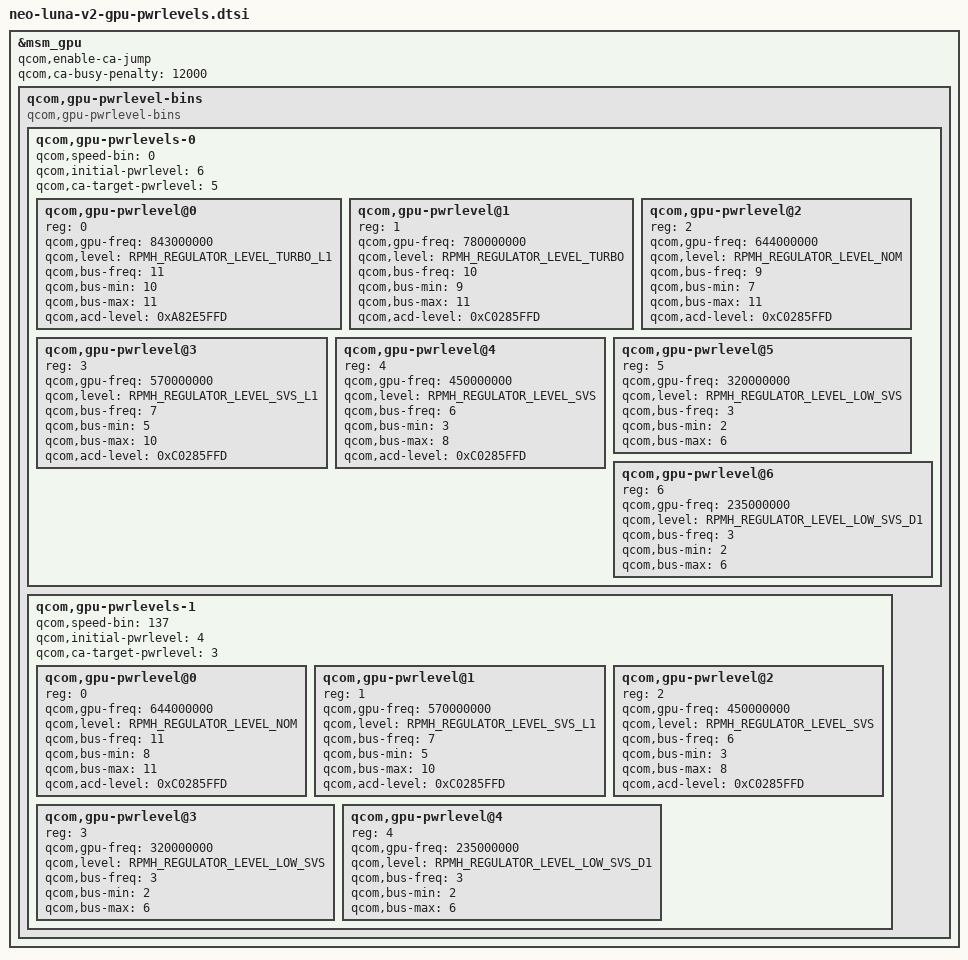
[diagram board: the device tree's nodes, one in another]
&msm_gpu {
	/* Power levels */

	/* Enable context aware freq. scaling */
	qcom,enable-ca-jump;

	/* Context aware jump busy penalty in us */
	qcom,ca-busy-penalty = <12000>;

	/*
	 * Speed-bin zero is default speed bin.
	 * For rest of the speed bins, speed-bin value
	 * is calculated as FMAX/4.8 MHz round up to zero
	 * decimal places plus two margin to account for
	 * clock jitters.
	 */
	qcom,gpu-pwrlevel-bins {
		#address-cells = <1>;
		#size-cells = <0>;

		compatible = "qcom,gpu-pwrlevel-bins";

		qcom,gpu-pwrlevels-0 {
			#address-cells = <1>;
			#size-cells = <0>;

			qcom,speed-bin = <0>;

			qcom,initial-pwrlevel = <6>;
			qcom,ca-target-pwrlevel = <5>;

			/* TURBO_L1 */
			qcom,gpu-pwrlevel@0 {
				reg = <0>;
				qcom,gpu-freq = <843000000>;
				qcom,level = <RPMH_REGULATOR_LEVEL_TURBO_L1>;
				qcom,bus-freq = <11>;
				qcom,bus-min = <10>;
				qcom,bus-max = <11>;

				qcom,acd-level = <0xA82E5FFD>;
			};

			/* TURBO */
			qcom,gpu-pwrlevel@1 {
				reg = <1>;
				qcom,gpu-freq = <780000000>;
				qcom,level = <RPMH_REGULATOR_LEVEL_TURBO>;
				qcom,bus-freq = <10>;
				qcom,bus-min = <9>;
				qcom,bus-max = <11>;

				qcom,acd-level = <0xC0285FFD>;
			};

			/* NOM */
			qcom,gpu-pwrlevel@2 {
				reg = <2>;
				qcom,gpu-freq = <644000000>;
				qcom,level = <RPMH_REGULATOR_LEVEL_NOM>;
				qcom,bus-freq = <9>;
				qcom,bus-min = <7>;
				qcom,bus-max = <11>;

				qcom,acd-level = <0xC0285FFD>;
			};

			/* SVS_L1 */
			qcom,gpu-pwrlevel@3 {
				reg = <3>;
				qcom,gpu-freq = <570000000>;
				qcom,level = <RPMH_REGULATOR_LEVEL_SVS_L1>;
				qcom,bus-freq = <7>;
				qcom,bus-min = <5>;
				qcom,bus-max = <10>;

				qcom,acd-level = <0xC0285FFD>;
			};

			/* SVS */
			qcom,gpu-pwrlevel@4 {
				reg = <4>;
				qcom,gpu-freq = <450000000>;
				qcom,level = <RPMH_REGULATOR_LEVEL_SVS>;
				qcom,bus-freq = <6>;
				qcom,bus-min = <3>;
				qcom,bus-max = <8>;

				qcom,acd-level = <0xC0285FFD>;
			};

			/* LOW SVS */
			qcom,gpu-pwrlevel@5 {
				reg = <5>;
				qcom,gpu-freq = <320000000>;
				qcom,level = <RPMH_REGULATOR_LEVEL_LOW_SVS>;
				qcom,bus-freq = <3>;
				qcom,bus-min = <2>;
				qcom,bus-max = <6>;
			};

			/* LOW SVS_D1 */
			qcom,gpu-pwrlevel@6 {
				reg = <6>;
				qcom,gpu-freq = <235000000>;
				qcom,level = <RPMH_REGULATOR_LEVEL_LOW_SVS_D1>;
				qcom,bus-freq = <3>;
				qcom,bus-min = <2>;
				qcom,bus-max = <6>;
			};
		};

		qcom,gpu-pwrlevels-1 {
			#address-cells = <1>;
			#size-cells = <0>;

			qcom,speed-bin = <137>;

			qcom,initial-pwrlevel = <4>;
			qcom,ca-target-pwrlevel = <3>;

			/* NOM */
			qcom,gpu-pwrlevel@0 {
				reg = <0>;
				qcom,gpu-freq = <644000000>;
				qcom,level = <RPMH_REGULATOR_LEVEL_NOM>;
				qcom,bus-freq = <11>;
				qcom,bus-min = <8>;
				qcom,bus-max = <11>;

				qcom,acd-level = <0xC0285FFD>;
			};

			/* SVS_L1 */
			qcom,gpu-pwrlevel@1 {
				reg = <1>;
				qcom,gpu-freq = <570000000>;
				qcom,level = <RPMH_REGULATOR_LEVEL_SVS_L1>;
				qcom,bus-freq = <7>;
				qcom,bus-min = <5>;
				qcom,bus-max = <10>;

				qcom,acd-level = <0xC0285FFD>;
			};

			/* SVS */
			qcom,gpu-pwrlevel@2 {
				reg = <2>;
				qcom,gpu-freq = <450000000>;
				qcom,level = <RPMH_REGULATOR_LEVEL_SVS>;
				qcom,bus-freq = <6>;
				qcom,bus-min = <3>;
				qcom,bus-max = <8>;

				qcom,acd-level = <0xC0285FFD>;
			};

			/* LOW SVS */
			qcom,gpu-pwrlevel@3 {
				reg = <3>;
				qcom,gpu-freq = <320000000>;
				qcom,level = <RPMH_REGULATOR_LEVEL_LOW_SVS>;
				qcom,bus-freq = <3>;
				qcom,bus-min = <2>;
				qcom,bus-max = <6>;
			};

			/* LOW SVS_D1 */
			qcom,gpu-pwrlevel@4 {
				reg = <4>;
				qcom,gpu-freq = <235000000>;
				qcom,level = <RPMH_REGULATOR_LEVEL_LOW_SVS_D1>;
				qcom,bus-freq = <3>;
				qcom,bus-min = <2>;
				qcom,bus-max = <6>;
			};
		};
	};
};
